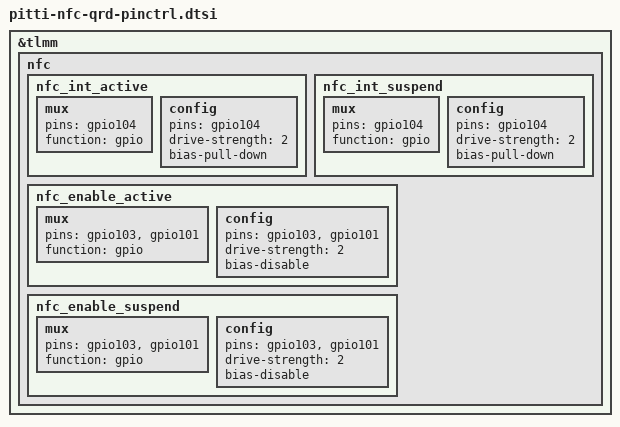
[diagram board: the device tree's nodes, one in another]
&tlmm {
	nfc {
		nfc_int_active: nfc_int_active {
			/* active state */
			mux {
				/* NFC Read Interrupt */
				pins = "gpio104";
				function = "gpio";
			};

			config {
				pins = "gpio104";
				drive-strength = <2>; /* 2 MA */
				bias-pull-down;
			};
		};

		nfc_int_suspend: nfc_int_suspend {
			/* sleep state */
			mux {
				/* NFC Read Interrupt */
				pins = "gpio104";
				function = "gpio";
			};

			config {
				pins = "gpio104";
				drive-strength = <2>; /* 2 MA */
				bias-pull-down;
			};
		};

		nfc_enable_active: nfc_enable_active {
			mux {
				/* Enable and Firmware gpios */
				pins = "gpio103", "gpio101";
				function = "gpio";
			};

			config {
				pins = "gpio103", "gpio101";
				drive-strength = <2>; /* 2 MA */
				bias-disable;
			};
		};

		nfc_enable_suspend: nfc_enable_suspend {
			mux {
				pins = "gpio103", "gpio101";
				function = "gpio";
			};

			config {
				pins = "gpio103", "gpio101";
				drive-strength = <2>; /* 2 MA */
				bias-disable;
			};
		};
	}; //nfc
}; //tlmm
